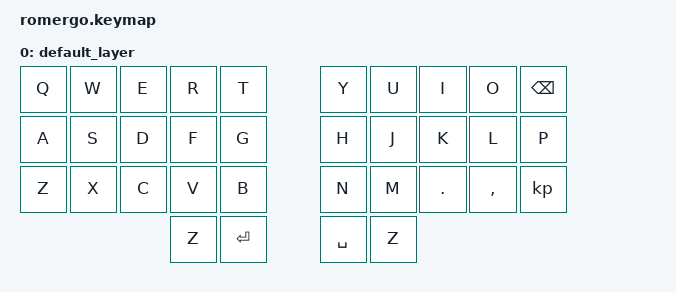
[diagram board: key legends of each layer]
#include <behaviors.dtsi>
#include <dt-bindings/zmk/keys.h>

/ {
    keymap {
        compatible = "zmk,keymap";

        default_layer { // Layer 0

            bindings = <
                &kp Q    &kp W    &kp E    &kp R    &kp T    &kp Y    &kp U    &kp I    &kp O    &kp BSPC 
                &kp A    &kp S    &kp D    &kp F    &kp G    &kp H    &kp J    &kp K    &kp L    &kp P
                &kp Z    &kp X    &kp C    &kp V    &kp B    &kp N    &kp M    &kp DOT  &kp COMMA  &kp 
                                        &kp Z    &kp ENTER    &kp SPACE    &kp Z 
            >;                             
        };
    };
 };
